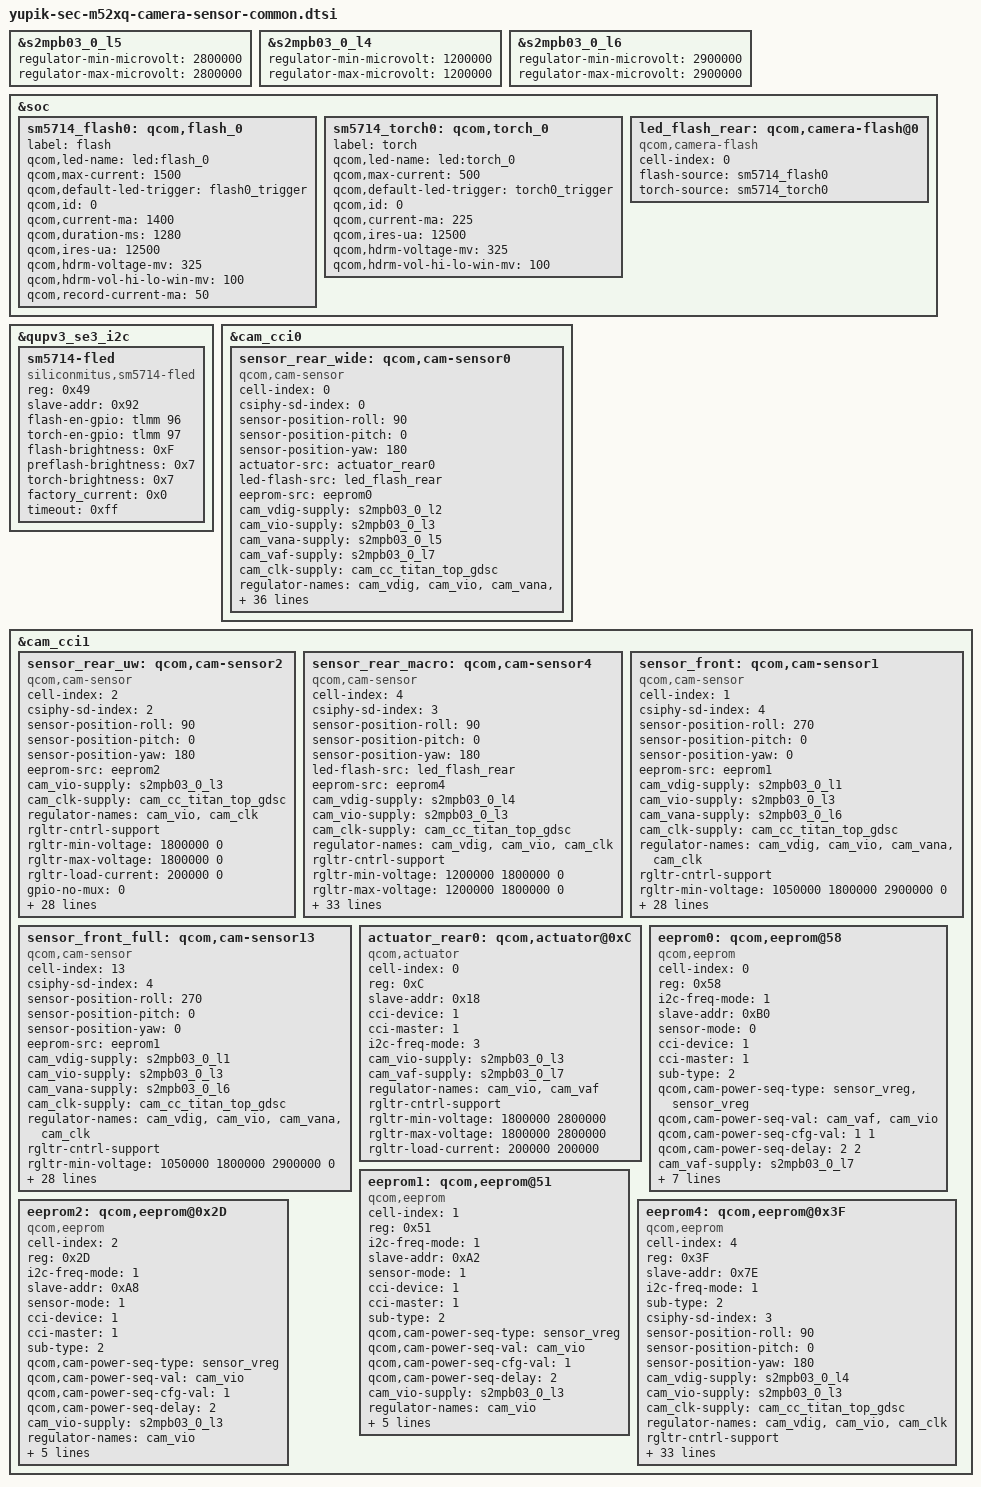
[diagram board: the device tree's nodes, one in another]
/*
 * Copyright (c) 2019, The Linux Foundation. All rights reserved.
 *
 * This program is free software; you can redistribute it and/or modify
 * it under the terms of the GNU General Public License version 2 and
 * only version 2 as published by the Free Software Foundation.
 *
 * This program is distributed in the hope that it will be useful,
 * but WITHOUT ANY WARRANTY; without even the implied warranty of
 * MERCHANTABILITY or FITNESS FOR A PARTICULAR PURPOSE.  See the
 * GNU General Public License for more details.
 */

#include <dt-bindings/clock/qcom,camcc-yupik.h>

#include <dt-bindings/regulator/qcom,rpmh-regulator-levels.h>

&s2mpb03_0_l5{
	regulator-min-microvolt = <2800000>;
	regulator-max-microvolt = <2800000>;
};

&s2mpb03_0_l4{
	regulator-min-microvolt = <1200000>;
	regulator-max-microvolt = <1200000>;
};

&s2mpb03_0_l6{
	regulator-min-microvolt = <2900000>;
	regulator-max-microvolt = <2900000>;
};

&soc {
	sm5714_flash0: qcom,flash_0 {
		label = "flash";
		qcom,led-name = "led:flash_0";
		qcom,max-current = <1500>;
		qcom,default-led-trigger = "flash0_trigger";
		qcom,id = <0>;
		qcom,current-ma = <1400>;
		qcom,duration-ms = <1280>;
		qcom,ires-ua = <12500>;
		qcom,hdrm-voltage-mv = <325>;
		qcom,hdrm-vol-hi-lo-win-mv = <100>;
		qcom,record-current-ma = <50>;
	};

	sm5714_torch0: qcom,torch_0 {
		label = "torch";
		qcom,led-name = "led:torch_0";
		qcom,max-current = <500>;
		qcom,default-led-trigger = "torch0_trigger";
		qcom,id = <0>;
		qcom,current-ma = <225>;
		qcom,ires-ua = <12500>;
		qcom,hdrm-voltage-mv = <325>;
		qcom,hdrm-vol-hi-lo-win-mv = <100>;
	};

	led_flash_rear: qcom,camera-flash@0 {
		cell-index = <0>;
		compatible = "qcom,camera-flash";
		flash-source = <&sm5714_flash0>;
		torch-source = <&sm5714_torch0>;
		status = "ok";
	};
};

// Select qupv3_se3_i2c since its paired with IF_PMIC_SDA_1P8 / IF_PMIC_SCL_1P8 (gpio12 / 13)
&qupv3_se3_i2c {
	status = "ok";

	sm5714-fled {
		compatible = "siliconmitus,sm5714-fled";
		reg = <0x49>;
		status = "okay";
		slave-addr = <0x92>;
		flash-en-gpio = <&tlmm 96 0>; //CAM_FLASH_EN
		torch-en-gpio = <&tlmm 97 0>; //CAM_TORCH_EN
		flash-brightness = <0xF>; //0x0(300mA) ~ 0xF(1500mA) : 50mA Step
		preflash-brightness = <0x7>;
		torch-brightness = <0x7>; //0x0(50mA) ~ 0x7(225mA) : 25mA Step
		factory_current = <0x0>; //0x0(300mA)
		timeout = <0xff>;
	};
};

&cam_cci0 {
// RCAM1 Wide 64M S5KGW3
	sensor_rear_wide: qcom,cam-sensor0 {
		cell-index = <0>;
		compatible = "qcom,cam-sensor";
		csiphy-sd-index = <0>;
		sensor-position-roll = <90>;
		sensor-position-pitch = <0>;
		sensor-position-yaw = <180>;

		actuator-src = <&actuator_rear0>;
		led-flash-src = <&led_flash_rear>;
		eeprom-src = <&eeprom0>;

		// LDO
		cam_vdig-supply = <&s2mpb03_0_l2>; //RCAM1_DVDD_1P05
		cam_vio-supply = <&s2mpb03_0_l3>; //CAM_VDDIO_1P8
		cam_vana-supply = <&s2mpb03_0_l5>; //RCAM1_AVDD_2P8
		cam_vaf-supply = <&s2mpb03_0_l7>; //RCAM1_AFVDD_2P8
		cam_clk-supply = <&cam_cc_titan_top_gdsc>;
		regulator-names = "cam_vdig", "cam_vio", "cam_vana", "cam_vaf", "cam_clk" ;
		rgltr-cntrl-support;
		rgltr-min-voltage = <1100000 1800000 2800000 2800000 0>;
		rgltr-max-voltage = <1100000 1800000 2800000 2800000 0>;
		rgltr-load-current = <200000 200000 5000 200000 0>;
		// GPIO
		gpio-no-mux = <0>;
		use-shared-clk;
		pinctrl-names = "cam_default", "cam_suspend";
		pinctrl-0 = <&rcam1_mclk_active &rcam1_rst_active &cam_flash_active>;
		pinctrl-1 = <&rcam1_mclk_suspend &rcam1_rst_suspend &cam_flash_suspend>;

		gpios = <&tlmm 64 0>,  // MCLK
			<&tlmm 20 0>;  // RST

		gpio-reset = <1>;
		gpio-req-tbl-num = <0 1>;
		gpio-req-tbl-flags = <1 0>;
		gpio-req-tbl-label = "CAMIF_MCLK0", "CAM_RESET0";

		sensor-mode = <0>;
		cci-device = <0>;
		cci-master = <0>;
		status = "ok";
		clocks = <&camcc CAM_CC_MCLK0_CLK>;
		clock-names = "cam_clk";
		clock-cntl-level = "turbo";
		clock-rates = <19200000>;

		cam,isp = <0>;					// 0 : INT , 1 : EXT , 2 : SOC
		cam,cal_memory = <2>;			// 0 : N , 1 : FROM , 2 : EEPROM , 3 : OTP
		cam,read_version = <1>;			// 0 : SYSFS , 1 : CAMON
		cam,core_voltage = <1>;			// 0 : N , 1 : Y
		cam,upgrade = <2>;				// 0 : N , 1 : SYSFS , 2 : CAMON
		cam,fw_write = <3>;				// 0 : N , 1 : OS , 2 : SD , 3 : ALL
		cam,fw_dump = <1>;				// 0 : N , 1 : Y
		cam,companion_chip = <0>;		// 0 : N , 1 : Y
		cam,ois = <0>;					// 0 : N , 1 : Y
		cam,dual_open = <0>;			// 0 : N , 1 : Y
		cam,valid = <1>;				// 0 : N , 1 : Y

	};
};

&cam_cci1 {
// RCAM2 12M UltraWide UW IMX258
	sensor_rear_uw: qcom,cam-sensor2 {
		cell-index = <2>;
		compatible = "qcom,cam-sensor";
		csiphy-sd-index = <2>;
		sensor-position-roll = <90>;
		sensor-position-pitch = <0>;
		sensor-position-yaw = <180>;

		//actuator-src = <&actuator_rear0>;
		//led-flash-src = <&led_flash_rear>;
		eeprom-src = <&eeprom2>;

		// LDO
		cam_vio-supply = <&s2mpb03_0_l3>;   //CAM_VDDIO_1P8
		cam_clk-supply = <&cam_cc_titan_top_gdsc>;
		regulator-names = "cam_vio", "cam_clk";
		rgltr-cntrl-support;
		rgltr-min-voltage = <1800000 0>;
		rgltr-max-voltage = <1800000 0>;
		rgltr-load-current = <200000 0>;

		// GPIO
		gpio-no-mux = <0>;
		pinctrl-names = "cam_default", "cam_suspend";
		pinctrl-0 = <&rcam2_mclk_active &rcam2_rst_active &rcam2_vana_active>;
		pinctrl-1 = <&rcam2_mclk_suspend &rcam2_rst_suspend &rcam2_vana_suspend>;

		gpios = <&tlmm 66 0>,  // RCAM2_MCLK
			<&tlmm 77 0>,  // RCAM2_RST_N
			<&tlmm 15 0>;  // VANA : RCAM2_AVDD_2P8, VDIG : RCAM2_DVDD_1P2

		gpio-reset = <1>;
		gpio-vana = <2>;
		gpio-req-tbl-num = <0 1 2>;
		gpio-req-tbl-flags = <1 0 0>;
		gpio-req-tbl-label = "CAMIF_MCLK2",
					"CAM_RESET2",
					"CAM_VANA2";
		sensor-mode = <0>;
		cci-device = <1>;
		cci-master = <0>;
		status = "ok";
		clocks = <&camcc CAM_CC_MCLK2_CLK>;
		clock-names = "cam_clk";
		clock-cntl-level = "turbo";
		clock-rates = <19200000>;

		cam,isp = <0>;                  // 0 : INT , 1 : EXT , 2 : SOC
		cam,cal_memory = <2>;           // 0 : N , 1 : FROM , 2 : EEPROM , 3 : OTP
		cam,read_version = <0>;         // 0 : SYSFS , 1 : CAMON
		cam,core_voltage = <0>;         // 0 : N , 1 : Y
		cam,upgrade = <0>;              // 0 : N , 1 : SYSFS , 2 : CAMON
		cam,fw_write = <0>;             // 0 : N , 1 : OS , 2 : SD , 3 : ALL
		cam,fw_dump = <0>;              // 0 : N , 1 : Y
		cam,companion_chip = <0>;       // 0 : N , 1 : Y
		cam,ois = <0>;                  // 0 : N , 1 : Y
		cam,dual_open = <0>;            // 0 : N , 1 : Y
		cam,valid = <1>;                // 0 : N , 1 : Y
	};

// RCAM3 5M Macro GC5035
	sensor_rear_macro: qcom,cam-sensor4 {
		cell-index = <4>;
		compatible = "qcom,cam-sensor";
		csiphy-sd-index = <3>;
		sensor-position-roll = <90>;
		sensor-position-pitch = <0>;
		sensor-position-yaw = <180>;
		led-flash-src = <&led_flash_rear>;
		eeprom-src = <&eeprom4>;

		// LDO
		cam_vdig-supply = <&s2mpb03_0_l4>; //RCAM3_DVDD_1P2
		cam_vio-supply = <&s2mpb03_0_l3>; //CAM_VDDIO_1P8
		cam_clk-supply = <&cam_cc_titan_top_gdsc>;
		regulator-names = "cam_vdig", "cam_vio", "cam_clk";
		rgltr-cntrl-support;
		rgltr-min-voltage = <1200000 1800000 0>;
		rgltr-max-voltage = <1200000 1800000 0>;
		rgltr-load-current = <200000 200000  0>;
		use-shared-clk;
		// GPIO
		gpio-no-mux = <0>;
		pinctrl-names = "cam_default", "cam_suspend";
		pinctrl-0 = <&rcam3_mclk_active &rcam3_rst_active &rcam3_vana_active &cam_flash_active>;
		pinctrl-1 = <&rcam3_mclk_suspend &rcam3_rst_suspend &rcam3_vana_suspend &cam_flash_suspend>;

		gpios = <&tlmm 67 0>,  // RCAM3_MCLK
			<&tlmm 78 0>,  // RCAM3_RST_N
			<&tlmm 14 0>;  // VANA : RCAM3_AVDD_2P8

		gpio-reset = <1>;
		gpio-vana = <2>;
		gpio-req-tbl-num = <0 1 2>;
		gpio-req-tbl-flags = <1 0 0>;
		gpio-req-tbl-label = "CAMIF_MCLK3", "CAM_RESET3", "RCAM3_VANA";

		sensor-mode = <0>;
		cci-device = <1>;
		cci-master = <0>;
		status = "ok";
		clocks = <&camcc CAM_CC_MCLK3_CLK>;
		clock-names = "cam_clk";
		clock-cntl-level = "turbo";
		clock-rates = <24000000>;

		cam,isp = <0>;                  // 0 : INT , 1 : EXT , 2 : SOC
		cam,cal_memory = <2>;           // 0 : N , 1 : FROM , 2 : EEPROM , 3 : OTP
		cam,read_version = <0>;         // 0 : SYSFS , 1 : CAMON
		cam,core_voltage = <0>;         // 0 : N , 1 : Y
		cam,upgrade = <0>;              // 0 : N , 1 : SYSFS , 2 : CAMON
		cam,fw_write = <0>;             // 0 : N , 1 : OS , 2 : SD , 3 : ALL
		cam,fw_dump = <0>;              // 0 : N , 1 : Y
		cam,companion_chip = <0>;       // 0 : N , 1 : Y
		cam,ois = <1>;                  // 0 : N , 1 : Y
		cam,dual_open = <0>;            // 0 : N , 1 : Y
		cam,valid = <1>;                // 0 : N , 1 : Y
	};

// FCAM 32M IMX616
	sensor_front: qcom,cam-sensor1 {
		cell-index = <1>;
		compatible = "qcom,cam-sensor";
		csiphy-sd-index = <4>;
		sensor-position-roll = <270>;
		sensor-position-pitch = <0>;
		sensor-position-yaw = <0>;

		//actuator-src = <&actuator_rear0>;
		//led-flash-src = <&led_flash_rear>;
		eeprom-src = <&eeprom1>;

		// LDO
		cam_vdig-supply = <&s2mpb03_0_l1>; //FCAM_DVDD_1P05
		cam_vio-supply = <&s2mpb03_0_l3>; //CAM_VDDIO_1P8
		cam_vana-supply = <&s2mpb03_0_l6>; //FCAM_AVDD_2P9
		cam_clk-supply = <&cam_cc_titan_top_gdsc>;
		regulator-names = "cam_vdig", "cam_vio", "cam_vana", "cam_clk";
		rgltr-cntrl-support;
		rgltr-min-voltage = <1050000 1800000 2900000 0>;
		rgltr-max-voltage = <1050000 1800000 2900000 0>;
		rgltr-load-current = <200000 200000 5000 0>;
		// GPIO
		gpio-no-mux = <0>;
		pinctrl-names = "cam_default", "cam_suspend";
		pinctrl-0 = <&fcam_mclk_active &fcam_rst_active>;
		pinctrl-1 = <&fcam_mclk_suspend &fcam_rst_suspend>;
		use-shared-clk;
		gpios = <&tlmm 68 0>,  // FCAM_MCLK
			<&tlmm 79 0>;  // FCAM_RST_N

		gpio-reset = <1>;
		gpio-req-tbl-num = <0 1>;
		gpio-req-tbl-flags = <1 0>;
		gpio-req-tbl-label = "CAMIF_MCLK4", "CAM_RESET4";

		sensor-mode = <0>;
		cci-device = <1>;
		cci-master = <0>;
		status = "ok";
		clocks = <&camcc CAM_CC_MCLK4_CLK>;
		clock-names = "cam_clk";
		clock-cntl-level = "turbo";
		clock-rates = <24000000>;

		cam,isp = <0>;                  // 0 : INT , 1 : EXT , 2 : SOC
		cam,cal_memory = <2>;           // 0 : N , 1 : FROM , 2 : EEPROM , 3 : OTP
		cam,read_version = <0>;         // 0 : SYSFS , 1 : CAMON
		cam,core_voltage = <0>;         // 0 : N , 1 : Y
		cam,upgrade = <0>;              // 0 : N , 1 : SYSFS , 2 : CAMON
		cam,fw_write = <0>;             // 0 : N , 1 : OS , 2 : SD , 3 : ALL
		cam,fw_dump = <0>;              // 0 : N , 1 : Y
		cam,companion_chip = <0>;       // 0 : N , 1 : Y
		cam,ois = <0>;                  // 0 : N , 1 : Y
		cam,dual_open = <0>;            // 0 : N , 1 : Y
		cam,valid = <1>;                // 0 : N , 1 : Y
	};

// Front Full IMX616
	sensor_front_full: qcom,cam-sensor13 {
		cell-index = <13>;
		compatible = "qcom,cam-sensor";
		csiphy-sd-index = <4>;
		sensor-position-roll = <270>;
		sensor-position-pitch = <0>;
		sensor-position-yaw = <0>;

		//actuator-src = <&actuator_rear0>;
		//led-flash-src = <&led_flash_rear>;
		eeprom-src = <&eeprom1>;

		// LDO
		cam_vdig-supply = <&s2mpb03_0_l1>; //FCAM_DVDD_1P05
		cam_vio-supply = <&s2mpb03_0_l3>; //CAM_VDDIO_1P8
		cam_vana-supply = <&s2mpb03_0_l6>; //FCAM_AVDD_2P9
		cam_clk-supply = <&cam_cc_titan_top_gdsc>;
		regulator-names = "cam_vdig", "cam_vio", "cam_vana", "cam_clk";
		rgltr-cntrl-support;
		rgltr-min-voltage = <1050000 1800000 2900000 0>;
		rgltr-max-voltage = <1050000 1800000 2900000 0>;
		rgltr-load-current = <200000 200000 5000 0>;
		// GPIO
		gpio-no-mux = <0>;
		pinctrl-names = "cam_default", "cam_suspend";
		pinctrl-0 = <&fcam_mclk_active &fcam_rst_active>;
		pinctrl-1 = <&fcam_mclk_suspend &fcam_rst_suspend>;
		use-shared-clk;

		gpios = <&tlmm 68 0>,  // FCAM_MCLK
			<&tlmm 79 0>;  // FCAM_RST_N

		gpio-reset = <1>;
		gpio-req-tbl-num = <0 1>;
		gpio-req-tbl-flags = <1 0>;
		gpio-req-tbl-label = "CAMIF_MCLK4", "CAM_RESET4";

		sensor-mode = <0>;
		cci-device = <1>;
		cci-master = <0>;
		status = "ok";
		clocks = <&camcc CAM_CC_MCLK4_CLK>;
		clock-names = "cam_clk";
		clock-cntl-level = "turbo";
		clock-rates = <24000000>;

		cam,isp = <0>;                  // 0 : INT , 1 : EXT , 2 : SOC
		cam,cal_memory = <2>;           // 0 : N , 1 : FROM , 2 : EEPROM , 3 : OTP
		cam,read_version = <0>;         // 0 : SYSFS , 1 : CAMON
		cam,core_voltage = <0>;         // 0 : N , 1 : Y
		cam,upgrade = <0>;              // 0 : N , 1 : SYSFS , 2 : CAMON
		cam,fw_write = <0>;             // 0 : N , 1 : OS , 2 : SD , 3 : ALL
		cam,fw_dump = <0>;              // 0 : N , 1 : Y
		cam,companion_chip = <0>;       // 0 : N , 1 : Y
		cam,ois = <0>;                  // 0 : N , 1 : Y
		cam,dual_open = <0>;            // 0 : N , 1 : Y
		cam,valid = <1>;                // 0 : N , 1 : Y
	};
	
	actuator_rear0: qcom,actuator@0xC {
		cell-index = <0>;
		reg = <0xC>;
		slave-addr = <0x18>;
		cci-device = <1>;
		cci-master = <1>;
		compatible = "qcom,actuator";
		i2c-freq-mode = <3>;
		cam_vio-supply = <&s2mpb03_0_l3>; //CAM_VDDIO_1P8
		cam_vaf-supply = <&s2mpb03_0_l7>; //RCAM1_AFVDD_2P8
		regulator-names = "cam_vio","cam_vaf";
		rgltr-cntrl-support;
        	rgltr-min-voltage = <1800000 2800000>;
        	rgltr-max-voltage = <1800000 2800000>;
		rgltr-load-current = <200000 200000>;
	};
	
	eeprom0: qcom,eeprom@58 {
		cell-index = <0>;
		reg = <0x58>;
		compatible = "qcom,eeprom";
		i2c-freq-mode = <1>;
		slave-addr = <0xB0>;
		sensor-mode = <0>;
		cci-device = <1>;
		cci-master = <1>;
		sub-type = <2>;
		
		qcom,cam-power-seq-type = "sensor_vreg", "sensor_vreg";
		qcom,cam-power-seq-val = "cam_vaf", "cam_vio";
		qcom,cam-power-seq-cfg-val = <1 1>;
		qcom,cam-power-seq-delay = <2 2>;

		cam_vaf-supply = <&s2mpb03_0_l7>;
		cam_vio-supply = <&s2mpb03_0_l3>;

		regulator-names = "cam_vaf","cam_vio";
		rgltr-min-voltage = <2800000 1800000>;
		rgltr-max-voltage = <2800000 1800000>;
		rgltr-load-current = <200000 200000>;

		sensor-position = <0>;
		rgltr-cntrl-support;
	};
	
	eeprom1: qcom,eeprom@51 {
	cell-index = <1>;
	reg = <0x51>;
	compatible = "qcom,eeprom";
	i2c-freq-mode = <1>;
	slave-addr = <0xA2>;
	sensor-mode = <1>;
	cci-device = <1>;
	cci-master = <1>;
	sub-type = <2>;

	qcom,cam-power-seq-type = "sensor_vreg";
	qcom,cam-power-seq-val = "cam_vio";
	qcom,cam-power-seq-cfg-val = <1>;
	qcom,cam-power-seq-delay = <2>;

	cam_vio-supply = <&s2mpb03_0_l3>;
	regulator-names = "cam_vio";
	rgltr-min-voltage = <1800000>;
	rgltr-max-voltage = <1800000>;
	rgltr-load-current = <200000>;

	sensor-position = <1>;
	rgltr-cntrl-support;
	};

	eeprom2: qcom,eeprom@0x2D {
		cell-index = <2>;
		reg = <0x2D>;
		compatible = "qcom,eeprom";
		i2c-freq-mode = <1>;
		slave-addr = <0xA8>;
		sensor-mode = <1>;
		cci-device = <1>;
		cci-master = <1>;
		sub-type = <2>;

		qcom,cam-power-seq-type = "sensor_vreg";
		qcom,cam-power-seq-val = "cam_vio";
		qcom,cam-power-seq-cfg-val = <1>;
		qcom,cam-power-seq-delay = <2>;

		cam_vio-supply = <&s2mpb03_0_l3>;
		regulator-names = "cam_vio";
		rgltr-min-voltage = <1800000>;
		rgltr-max-voltage = <1800000>;
		rgltr-load-current = <200000>;

		sensor-position = <1>;
		rgltr-cntrl-support;
	};

	eeprom4: qcom,eeprom@0x3F {
		cell-index = <4>;
		reg = <0x3F>;
		slave-addr = <0x7E>;
		compatible = "qcom,eeprom";
		i2c-freq-mode = <1>;
		sub-type = <2>;

		csiphy-sd-index = <3>;
		sensor-position-roll = <90>;
		sensor-position-pitch = <0>;
		sensor-position-yaw = <180>;

		// LDO
		cam_vdig-supply = <&s2mpb03_0_l4>; //RCAM3_DVDD_1P2
		cam_vio-supply = <&s2mpb03_0_l3>; //CAM_VDDIO_1P8
		cam_clk-supply = <&cam_cc_titan_top_gdsc>;
		regulator-names = "cam_vdig", "cam_vio", "cam_clk";
		rgltr-cntrl-support;
		rgltr-min-voltage = <1200000 1800000 0>;
		rgltr-max-voltage = <1200000 1800000 0>;
		rgltr-load-current = <200000 200000  0>;
		use-shared-clk;

		// GPIO
		gpio-no-mux = <0>;
		pinctrl-names = "cam_default", "cam_suspend";
		pinctrl-0 = <&rcam3_mclk_active &rcam3_rst_active &rcam3_vana_active>;
		pinctrl-1 = <&rcam3_mclk_suspend &rcam3_rst_suspend &rcam3_vana_suspend>;

		gpios = <&tlmm 67 0>,  // RCAM3_MCLK
			<&tlmm 78 0>,  // RCAM3_RST_N
			<&tlmm 14 0>;  // VANA : RCAM3_AVDD_2P8

		gpio-reset = <1>;
		gpio-vana = <2>;
		gpio-req-tbl-num = <0 1 2>;
		gpio-req-tbl-flags = <1 0 0>;
		gpio-req-tbl-label = "CAMIF_MCLK3", "CAM_RESET3", "RCAM3_VANA";

		sensor-mode = <0>;
		cci-device = <1>;
		cci-master = <0>;
		status = "ok";
		clocks = <&camcc CAM_CC_MCLK3_CLK>;
		clock-names = "cam_clk";
		clock-cntl-level = "turbo";
		clock-rates = <24000000>;

		cam,isp = <0>;					// 0 : INT , 1 : EXT , 2 : SOC
		cam,cal_memory = <2>;			// 0 : N , 1 : FROM , 2 : EEPROM , 3 : OTP
		cam,read_version = <1>;			// 0 : SYSFS , 1 : CAMON
		cam,core_voltage = <1>;			// 0 : N , 1 : Y
		cam,upgrade = <2>;				// 0 : N , 1 : SYSFS , 2 : CAMON
		cam,fw_write = <3>;				// 0 : N , 1 : OS , 2 : SD , 3 : ALL
		cam,fw_dump = <1>;				// 0 : N , 1 : Y
		cam,companion_chip = <0>;		// 0 : N , 1 : Y
		cam,ois = <0>;					// 0 : N , 1 : Y
		cam,dual_open = <0>;			// 0 : N , 1 : Y
		cam,valid = <1>;				// 0 : N , 1 : Y
	};
};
